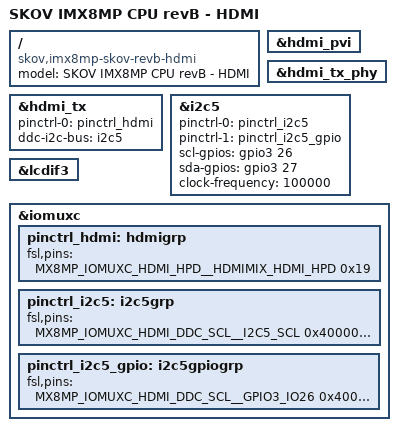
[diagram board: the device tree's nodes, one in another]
// SPDX-License-Identifier: (GPL-2.0 OR MIT)

/dts-v1/;

#include "imx8mp-skov-reva.dtsi"

/ {
	model = "SKOV IMX8MP CPU revB - HDMI";
	compatible = "skov,imx8mp-skov-revb-hdmi", "fsl,imx8mp";
};

&hdmi_pvi {
	status = "okay";
};

&hdmi_tx {
	pinctrl-names = "default";
	pinctrl-0 = <&pinctrl_hdmi>;
	ddc-i2c-bus = <&i2c5>;
	status = "okay";
};

&hdmi_tx_phy {
	status = "okay";
};

&i2c5 {
	pinctrl-names = "default", "gpio";
	pinctrl-0 = <&pinctrl_i2c5>;
	pinctrl-1 = <&pinctrl_i2c5_gpio>;
	scl-gpios = <&gpio3 26 (GPIO_ACTIVE_HIGH | GPIO_OPEN_DRAIN)>;
	sda-gpios = <&gpio3 27 (GPIO_ACTIVE_HIGH | GPIO_OPEN_DRAIN)>;
	clock-frequency = <100000>;
	status = "okay";
};

&lcdif3 {
	status = "okay";
};

&iomuxc {
	pinctrl_hdmi: hdmigrp {
		fsl,pins = <
			MX8MP_IOMUXC_HDMI_HPD__HDMIMIX_HDMI_HPD			0x19
		>;
	};

	pinctrl_i2c5: i2c5grp {
		fsl,pins = <
			MX8MP_IOMUXC_HDMI_DDC_SCL__I2C5_SCL			0x400001c2
			MX8MP_IOMUXC_HDMI_DDC_SDA__I2C5_SDA			0x400001c2
		>;
	};

	pinctrl_i2c5_gpio: i2c5gpiogrp {
		fsl,pins = <
			MX8MP_IOMUXC_HDMI_DDC_SCL__GPIO3_IO26			0x400001c2
			MX8MP_IOMUXC_HDMI_DDC_SDA__GPIO3_IO27			0x400001c2
		>;
	};
};
